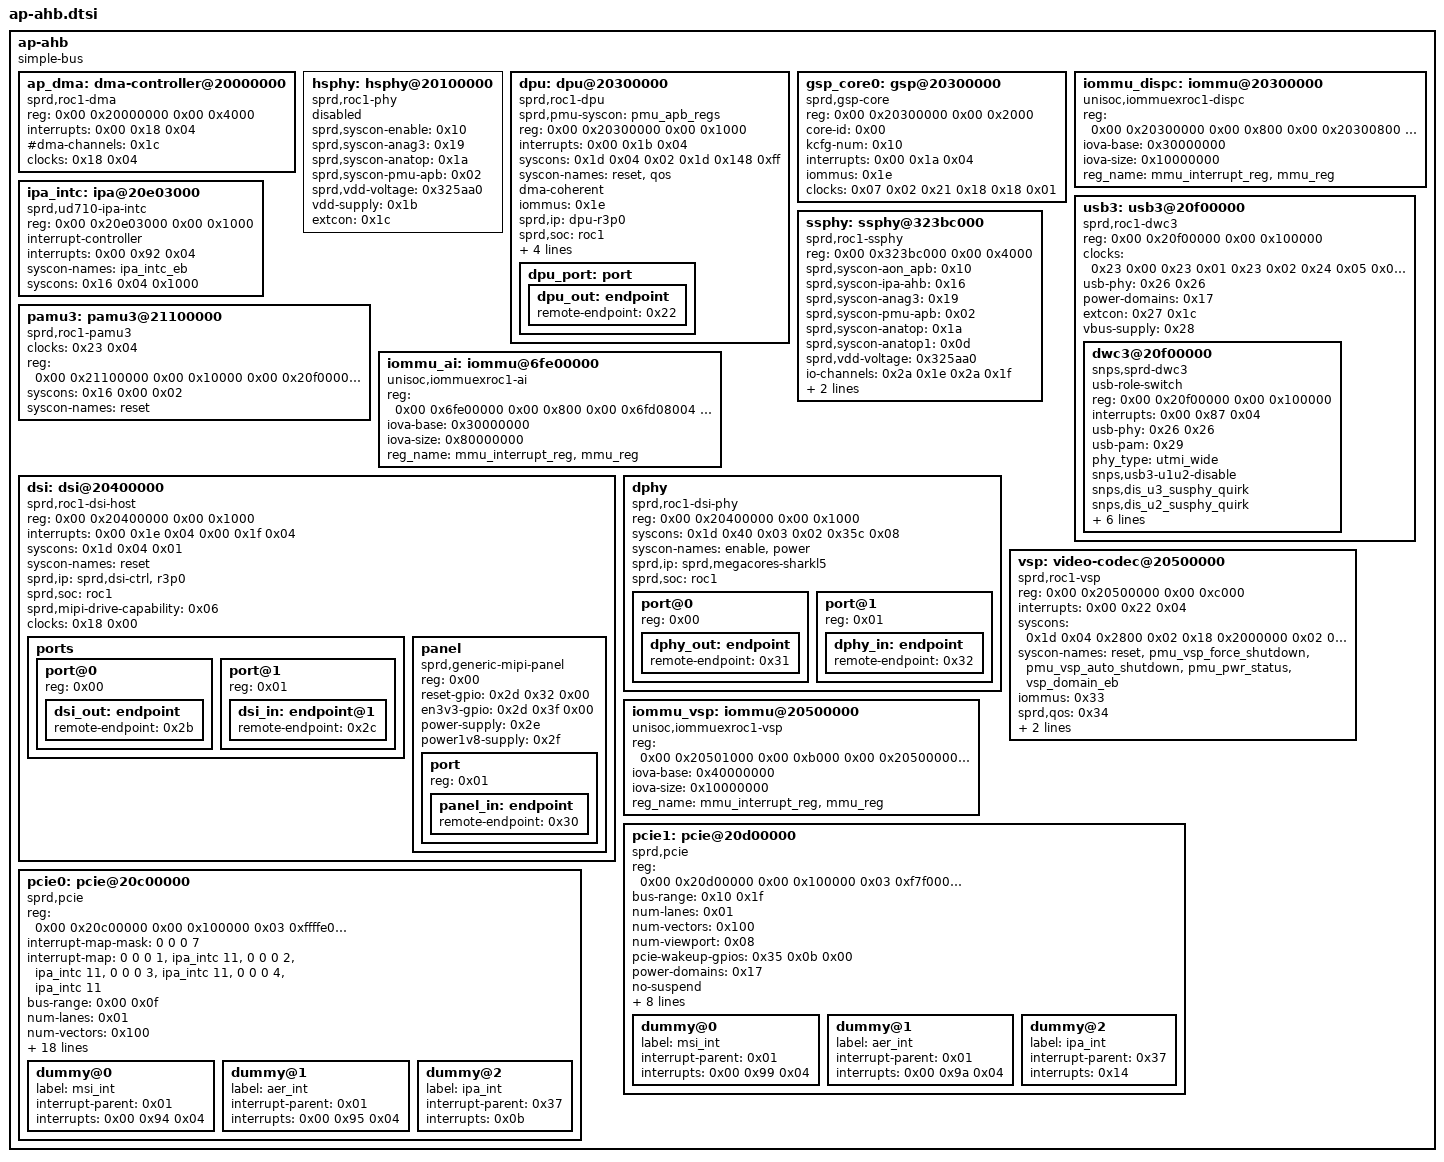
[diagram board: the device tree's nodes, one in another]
/*
 * iclass-c8pro hardware description; included in place from the board DTS.
 * Copyright (C) 2026 Evarentha - Linux 5.15 board port changes.
 */

		ap-ahb {
			compatible = "simple-bus";
			#address-cells = <0x02>;
			#size-cells = <0x02>;
			ranges;

			ap_dma: dma-controller@20000000 {
				compatible = "sprd,roc1-dma";
				reg = <0x00 0x20000000 0x00 0x4000>;
				interrupts = <0x00 0x18 0x04>;
				#dma-cells = <0x01>;
				#dma-channels = <0x1c>;
				clock-names = "enable";
				clocks = <0x18 0x04>;
				phandle = <0x116>;
			};

			hsphy: hsphy@20100000 {
				compatible = "sprd,roc1-phy";
				sprd,syscon-enable = <0x10>;
				sprd,syscon-anag3 = <0x19>;
				sprd,syscon-anatop = <0x1a>;
				sprd,syscon-pmu-apb = <0x02>;
				sprd,vdd-voltage = <0x325aa0>;
				#phy-cells = <0x00>;
				vdd-supply = <0x1b>;
				extcon = <0x1c>;
				status = "disabled";
				phandle = <0x7c>;
			};

			dpu: dpu@20300000 {
				compatible = "sprd,roc1-dpu";
				sprd,pmu-syscon = <&pmu_apb_regs>;
				reg = <0x00 0x20300000 0x00 0x1000>;
				interrupts = <0x00 0x1b 0x04>;
				status = "okay";
				syscons = <0x1d 0x04 0x02 0x1d 0x148 0xff>;
				syscon-names = "reset", "qos";
				dma-coherent;
				iommus = <0x1e>;
				sprd,ip = "dpu-r3p0";
				sprd,soc = "roc1";
				sprd,qos = <0x1f>;
				sprd,wb-memory = <0x20>;
				clock-names = "clk_src_128m", "clk_src_153m6", "clk_src_192m", "clk_src_256m", "clk_src_307m2", "clk_src_384m", "clk_dpu_core", "clk_dpu_dpi", "clk_ap_ahb_disp_eb";
				clocks = <0x07 0x0a 0x07 0x0f 0x07 0x03 0x07 0x09 0x07 0x0c 0x07 0x02 0x21 0x18 0x21 0x19 0x18 0x01>;
				phandle = <0x151>;

				dpu_port: port {
					phandle = <0x106>;

					dpu_out: endpoint {
						remote-endpoint = <0x22>;
						phandle = <0x2c>;
					};
				};
			};

			gsp_core0: gsp@20300000 {
				compatible = "sprd,gsp-core";
				reg = <0x00 0x20300000 0x00 0x2000>;
				core-id = <0x00>;
				kcfg-num = <0x10>;
				interrupts = <0x00 0x1a 0x04>;
				iommus = <0x1e>;
				clock-names = "clk_dpu_core_src", "clk_dpu_core", "clk_ap_ahb_disp_eb";
				clocks = <0x07 0x02 0x21 0x18 0x18 0x01>;
				phandle = <0xee>;
			};

			iommu_dispc: iommu@20300000 {
				compatible = "unisoc,iommuexroc1-dispc";
				reg = <0x00 0x20300000 0x00 0x800 0x00 0x20300800 0x00 0x80>;
				iova-base = <0x30000000>;
				iova-size = <0x10000000>;
				reg_name = "mmu_interrupt_reg", "mmu_reg";
				status = "okay";
				#iommu-cells = <0x00>;
				phandle = <0x1e>;
			};

			ipa_intc: ipa@20e03000 {
				compatible = "sprd,ud710-ipa-intc";
				reg = <0x00 0x20e03000 0x00 0x1000>;
				interrupt-controller;
				interrupts = <0x00 0x92 0x04>;
				#interrupt-cells = <0x01>;
				syscon-names = "ipa_intc_eb";
				syscons = <0x16 0x04 0x1000>;
				phandle = <0x37>;
			};

			usb3: usb3@20f00000 {
				compatible = "sprd,roc1-dwc3";
				reg = <0x00 0x20f00000 0x00 0x100000>;
				status = "okay";
				#address-cells = <0x02>;
				#size-cells = <0x02>;
				ranges;
				clocks = <0x23 0x00 0x23 0x01 0x23 0x02 0x24 0x05 0x07 0x06 0x25>;
				clock-names = "core_clk", "ref_clk", "susp_clk", "ipa_usb_ref", "ipa_usb_ref_source", "ipa_usb_ref_default";
				usb-phy = <0x26 0x26>;
				power-domains = <0x17>;
				extcon = <0x27 0x1c>;
				vbus-supply = <0x28>;
				phandle = <0x152>;

				dwc3@20f00000 {
					compatible = "snps,sprd-dwc3";
					usb-role-switch;
					reg = <0x00 0x20f00000 0x00 0x100000>;
					interrupts = <0x00 0x87 0x04>;
					interrupt-names = "irq";
					usb-phy = <0x26 0x26>;
					usb-pam = <0x29>;
					phy_type = "utmi_wide";
					snps,usb3-u1u2-disable;
					snps,dis_u3_susphy_quirk;
					snps,dis_u2_susphy_quirk;
					snps,overlap_check_quirk;
					snps,ep_out_aligned_size_quirk;
					snps,disconnect_event_quirk;
					snps,usb3_slow_suspend;
					snps,host_suspend_capable;
					snps,dis-del-phy-power-chg-quirk;
				};
			};

			pamu3: pamu3@21100000 {
				compatible = "sprd,roc1-pamu3";
				clocks = <0x23 0x04>;
				clock-names = "pamu3_clk";
				reg = <0x00 0x21100000 0x00 0x10000 0x00 0x20f00000 0x00 0x100000>;
				reg-names = "pamu3_glb_regs", "dwc3_core_regs";
				syscons = <0x16 0x00 0x02>;
				syscon-names = "reset";
				phandle = <0x29>;
			};

			ssphy: ssphy@323bc000 {
				compatible = "sprd,roc1-ssphy";
				#phy-cells = <0x00>;
				reg = <0x00 0x323bc000 0x00 0x4000>;
				reg-names = "phy_glb_regs";
				sprd,syscon-aon_apb = <0x10>;
				sprd,syscon-ipa-ahb = <0x16>;
				sprd,syscon-anag3 = <0x19>;
				sprd,syscon-pmu-apb = <0x02>;
				sprd,syscon-anatop = <0x1a>;
				sprd,syscon-anatop1 = <0x0d>;
				sprd,vdd-voltage = <0x325aa0>;
				io-channels = <0x2a 0x1e 0x2a 0x1f>;
				io-channel-names = "dp", "dm";
				status = "okay";
				vdd-supply = <0x1b>;
				extcon = <0x27>;
				phandle = <0x26>;
			};

			iommu_ai: iommu@6fe00000 {
				compatible = "unisoc,iommuexroc1-ai";
				reg = <0x00 0x6fe00000 0x00 0x800 0x00 0x6fd08004 0x00 0x80>;
				iova-base = <0x30000000>;
				iova-size = <0x80000000>;
				reg_name = "mmu_interrupt_reg", "mmu_reg";
				status = "okay";
				#iommu-cells = <0x00>;
				phandle = <0xb5>;
			};

			dsi: dsi@20400000 {
				compatible = "sprd,roc1-dsi-host";
				reg = <0x00 0x20400000 0x00 0x1000>;
				interrupts = <0x00 0x1e 0x04 0x00 0x1f 0x04>;
				status = "okay";
				syscons = <0x1d 0x04 0x01>;
				syscon-names = "reset";
				sprd,ip = "sprd,dsi-ctrl", "r3p0";
				sprd,soc = "roc1";
				sprd,mipi-drive-capability = <0x06>;
				clock-names = "clk_ap_ahb_dsi_eb";
				clocks = <0x18 0x00>;
				#address-cells = <0x01>;
				#size-cells = <0x00>;
				phandle = <0x153>;

				ports {
					#address-cells = <0x01>;
					#size-cells = <0x00>;

					port@0 {
						reg = <0x00>;

						dsi_out: endpoint {
							remote-endpoint = <0x2b>;
							phandle = <0x32>;
						};
					};

					port@1 {
						reg = <0x01>;

						dsi_in: endpoint@1 {
							remote-endpoint = <0x2c>;
							phandle = <0x22>;
						};
					};
				};

				panel: panel {
					compatible = "sprd,generic-mipi-panel";
					#address-cells = <0x01>;
					#size-cells = <0x00>;
					reg = <0x00>;
					reset-gpio = <0x2d 0x32 0x00>;
					en3v3-gpio = <0x2d 0x3f 0x00>;
					power-supply = <0x2e>;
					power1v8-supply = <0x2f>;
					phandle = <0x154>;

					port {
						reg = <0x01>;

						panel_in: endpoint {
							remote-endpoint = <0x30>;
							phandle = <0x31>;
						};
					};
				};
			};

			dphy: dphy {
				compatible = "sprd,roc1-dsi-phy";
				#address-cells = <0x01>;
				#size-cells = <0x00>;
				reg = <0x00 0x20400000 0x00 0x1000>;
				status = "okay";
				syscons = <0x1d 0x40 0x03 0x02 0x35c 0x08>;
				syscon-names = "enable", "power";
				sprd,ip = "sprd,megacores-sharkl5";
				sprd,soc = "roc1";
				phandle = <0x155>;

				port@0 {
					reg = <0x00>;

					dphy_out: endpoint {
						remote-endpoint = <0x31>;
						phandle = <0x30>;
					};
				};

				port@1 {
					reg = <0x01>;

					dphy_in: endpoint {
						remote-endpoint = <0x32>;
						phandle = <0x2b>;
					};
				};
			};

			vsp: video-codec@20500000 {
				compatible = "sprd,roc1-vsp";
				reg = <0x00 0x20500000 0x00 0xc000>;
				interrupts = <0x00 0x22 0x04>;
				syscons = <0x1d 0x04 0x2800 0x02 0x18 0x2000000 0x02 0x18 0x1000000 0x02 0x584 0xff0000 0x10 0x04 0x20>;
				syscon-names = "reset", "pmu_vsp_force_shutdown", "pmu_vsp_auto_shutdown", "pmu_pwr_status", "vsp_domain_eb";
				iommus = <0x33>;
				sprd,qos = <0x34>;
				status = "okay";
				clock-names = "clk_ahb_gate_vsp_eb", "clk_src_256m", "clk_src_307m2", "clk_src_384m", "clk_src_512m", "clk_vsp";
				clocks = <0x18 0x02 0x07 0x09 0x07 0x0c 0x07 0x02 0x07 0x08 0x21 0x17>;
				phandle = <0x156>;
			};

			iommu_vsp: iommu@20500000 {
				compatible = "unisoc,iommuexroc1-vsp";
				reg = <0x00 0x20501000 0x00 0xb000 0x00 0x20500000 0x00 0x80>;
				iova-base = <0x40000000>;
				iova-size = <0x10000000>;
				reg_name = "mmu_interrupt_reg", "mmu_reg";
				status = "okay";
				#iommu-cells = <0x00>;
				phandle = <0x33>;
			};

			pcie1: pcie@20d00000 {
				compatible = "sprd,pcie", "snps,dw-pcie";
				reg = <0x00 0x20d00000 0x00 0x100000 0x03 0xf7f00000 0x00 0x100000>;
				reg-names = "dbi", "config";
				#address-cells = <0x03>;
				#size-cells = <0x02>;
				device_type = "pci";
				ranges = <0x1000000 0x00 0x00 0x03 0xf7ef0000 0x00 0x10000 0x3000000 0x00 0x10000000 0x02 0x80000000 0x00 0x80000000>;
				bus-range = <0x10 0x1f>;
				num-lanes = <0x01>;
				num-vectors = <0x100>;
				num-viewport = <0x08>;
				pcie-wakeup-gpios = <0x35 0x0b 0x00>;
				status = "okay";
				power-domains = <0x17>;
				no-suspend;
				sprd,pcie-shutdown-syscons = <0x02 0x00 0x00 0x3cc 0x08 0x08 0x16 0x00 0x00 0x04 0x80 0x00 0x02 0x00 0x00 0xbc 0x2000 0x00 0x02 0x00 0x00 0xbc 0x100 0x00>;
				sprd,pcie-startup-syscons = <0x02 0x02 0x00 0x580 0xff000000 0x00 0x36 0x01 0x00 0x10 0x3000 0x1000 0x36 0x01 0x00 0x00 0x3e00 0x3e00 0x36 0x00 0x00 0x00 0x01 0x01 0x02 0x00 0x96 0xbc 0x100 0x100 0x16 0x00 0x96 0x04 0x80 0x80 0x02 0x00 0x7d0 0x3cc 0x08 0x00>;
				sprd,pcie-resume-syscons = <0x02 0x02 0x00 0x580 0xff000000 0x00 0x02 0x00 0x96 0xbc 0x100 0x100 0x16 0x00 0x96 0x04 0x80 0x80 0x02 0x00 0x7d0 0x3cc 0x08 0x00>;
				sprd,pcie-suspend-syscons = <0x02 0x00 0x00 0x3cc 0x08 0x08 0x16 0x00 0x00 0x04 0x80 0x00 0x02 0x00 0x00 0xbc 0x2000 0x00 0x02 0x00 0x00 0xbc 0x100 0x00>;
				phandle = <0x117>;

				dummy@0 {
					label = "msi_int";
					interrupt-parent = <0x01>;
					#interrupt-cells = <0x03>;
					interrupts = <0x00 0x99 0x04>;
				};

				dummy@1 {
					label = "aer_int";
					interrupt-parent = <0x01>;
					#interrupt-cells = <0x03>;
					interrupts = <0x00 0x9a 0x04>;
				};

				dummy@2 {
					label = "ipa_int";
					interrupt-parent = <0x37>;
					#interrupt-cells = <0x01>;
					interrupts = <0x14>;
				};
			};

			pcie0: pcie@20c00000 {
				compatible = "sprd,pcie", "snps,dw-pcie";
				reg = <0x00 0x20c00000 0x00 0x100000 0x03 0xffffe000 0x00 0x2000>;
				reg-names = "dbi", "config";
				#address-cells = <0x03>;
				#size-cells = <0x02>;
				device_type = "pci";
				#interrupt-cells = <1>;
				interrupt-map-mask = <0 0 0 7>;
				interrupt-map = <0 0 0 1 &ipa_intc 11>,
						<0 0 0 2 &ipa_intc 11>,
						<0 0 0 3 &ipa_intc 11>,
						<0 0 0 4 &ipa_intc 11>;
				ranges = <0x1000000 0x00 0x00 0x03 0xfffee000 0x00 0x10000 0x3000000 0x00 0x10000000 0x03 0xf8000000 0x00 0x7fee000>;
				bus-range = <0x00 0x0f>;
				num-lanes = <0x01>;
				num-vectors = <0x100>;
				num-viewport = <0x08>;
				pcie-wakeup-gpios = <0x35 0x0a 0x00>;
				status = "okay";
				power-domains = <0x17>;
				ep-poweron-late;
				sprd,pcie-startup-syscons = <0x38 0x01 0x00 0x08 0x100000 0x100000 0x02 0x00 0x00 0x800 0x10000 0x00 0x39 0x00 0x00 0x00 0x01 0x00 0x39 0x01 0x00 0x00 0x3e00 0x3e00 0x02 0x00 0x00 0xb8 0x100 0x100 0x02 0x00 0x00 0x4bc 0x04 0x04 0x02 0x02 0x00 0xd4 0xf000000 0x6000000 0x02 0x02 0x00 0x580 0xff000000 0x00 0x16 0x00 0x00 0x04 0x100 0x100 0x39 0x00 0x96 0x00 0x01 0x01 0x02 0x00 0x7d0 0x3cc 0x02 0x00>;
				sprd,pcie-shutdown-syscons = <0x02 0x00 0x00 0x3cc 0x02 0x02 0x39 0x00 0x00 0x00 0x01 0x00 0x16 0x00 0x00 0x04 0x100 0x00 0x02 0x00 0x00 0x4bc 0x04 0x00 0x02 0x00 0x00 0x35c 0x04 0x04 0x02 0x00 0x00 0xb8 0x2000 0x00 0x02 0x00 0x00 0xb8 0x100 0x00>;
				sprd,pcie-resume-syscons = <0x02 0x00 0xc8 0xb8 0x100 0x100 0x02 0x00 0x00 0x4bc 0x04 0x04 0x02 0x02 0x00 0xd4 0xf000000 0x6000000 0x02 0x02 0x00 0x580 0xff000000 0x00 0x16 0x00 0xc8 0x04 0x100 0x100 0x39 0x01 0x00 0x00 0x3e00 0x3e00 0x39 0x00 0x96 0x00 0x01 0x01 0x02 0x00 0x7d0 0x3cc 0x02 0x00>;
				sprd,pcie-suspend-syscons = <0x02 0x00 0x00 0x3cc 0x02 0x02 0x39 0x00 0x00 0x00 0x01 0x00 0x16 0x00 0x00 0x04 0x100 0x00 0x02 0x00 0x00 0x4bc 0x04 0x00 0x02 0x00 0x00 0x35c 0x04 0x04 0x02 0x00 0x00 0xb8 0x2000 0x00 0x02 0x00 0x00 0xb8 0x100 0x00>;
				sprd,pcie-aspml1p2-syscons = <0x3a 0x01 0x00 0xb4 0x800000 0x800000 0x3a 0x01 0x00 0xb4 0x10000000 0x10000000 0x02 0x01 0x00 0x3d8 0xff0000 0x4e0000 0x02 0x01 0x00 0x3d8 0xff 0x4e 0x02 0x01 0x00 0x68 0xff 0x05 0x02 0x01 0x00 0x800 0x10000 0x10000 0x02 0x01 0x00 0x800 0x01 0x00>;
				sprd,pcie-autogateclk-syscons = <0x02 0x01 0x00 0x800 0x10000 0x00 0x02 0x01 0x00 0x800 0x01 0x01>;
				sprd,pcie-notgateclk-syscons = <0x02 0x01 0x00 0x800 0x10000 0x10000 0x02 0x01 0x00 0x800 0x01 0x00>;
				phandle = <0x128>;

				dummy@0 {
					label = "msi_int";
					interrupt-parent = <0x01>;
					#interrupt-cells = <0x03>;
					interrupts = <0x00 0x94 0x04>;
				};

				dummy@1 {
					label = "aer_int";
					interrupt-parent = <0x01>;
					#interrupt-cells = <0x03>;
					interrupts = <0x00 0x95 0x04>;
				};

				dummy@2 {
					label = "ipa_int";
					interrupt-parent = <0x37>;
					#interrupt-cells = <0x01>;
					interrupts = <0x0b>;
				};
			};
		};

